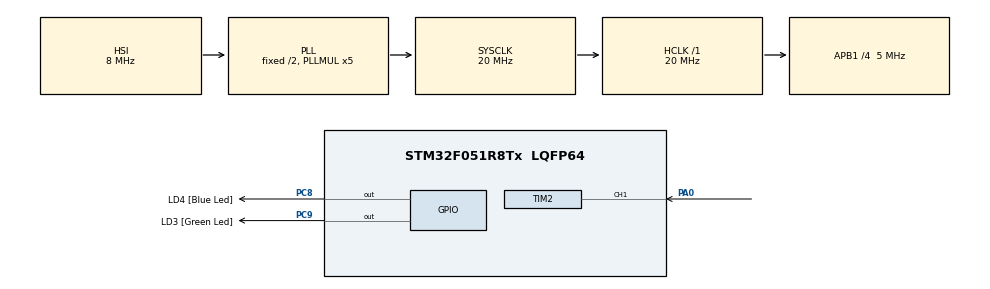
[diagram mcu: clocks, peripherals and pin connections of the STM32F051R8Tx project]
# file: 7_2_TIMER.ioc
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Mcu.Family=STM32F0
Mcu.Name=STM32F051R8Tx
Mcu.Package=LQFP64
NVIC.TIM2_IRQn=true\:0\:0\:false\:false\:true\:true\:true\:true
PA0.Signal=S_TIM2_CH1_ETR
PA13.GPIO_Label=SWDIO
PA13.Signal=SYS_SWDIO
PA14.GPIO_Label=SWCLK
PA14.Signal=SYS_SWCLK
PC8.GPIO_Label=LD4 [Blue Led]
PC8.Signal=GPIO_Output
PC9.GPIO_Label=LD3 [Green Led]
PC9.Signal=GPIO_Output
ProjectManager.HeapSize=0x200
ProjectManager.StackSize=0x400
ProjectManager.TargetToolchain=STM32CubeIDE
RCC.AHBFreq_Value=20000000
RCC.APB1CLKDivider=RCC_HCLK_DIV4
RCC.APB1Freq_Value=5000000
RCC.APB1TimFreq_Value=10000000
RCC.HCLKFreq_Value=20000000
RCC.PLLMUL=RCC_PLL_MUL5
RCC.SYSCLKFreq_VALUE=20000000
RCC.SYSCLKSource=RCC_SYSCLKSOURCE_PLLCLK
SH.S_TIM2_CH1_ETR.0=TIM2_CH1,Input_Capture1_from_TI1
TIM2.AutoReloadPreload=TIM_AUTORELOAD_PRELOAD_ENABLE
TIM2.Channel-Input_Capture1_from_TI1=TIM_CHANNEL_1
TIM2.Period=60000-1
TIM2.Prescaler=0
VP_TIM2_VS_ClockSourceINT.Mode=Internal
board=STM32F0DISCOVERY

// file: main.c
/* USER CODE BEGIN Header */
/**
  ******************************************************************************
  * @file           : main.c
  * @brief          : Main program body
  ******************************************************************************
  * @attention
  *
  * Copyright (c) 2023 STMicroelectronics.
  * All rights reserved.
  *
  * This software is licensed under terms that can be found in the LICENSE file
  * in the root directory of this software component.
  * If no LICENSE file comes with this software, it is provided AS-IS.
  *
  ******************************************************************************
  */
/* USER CODE END Header */
#include "main.h"

TIM_HandleTypeDef htim2;

void SystemClock_Config(void);
static void MX_GPIO_Init(void);
static void MX_TIM2_Init(void);

/* USER CODE BEGIN 0 */
float freq;
int ovc_value=0;
int start_flag=0;
int value_1=0;
int value_2=0;

/* USER CODE END 0 */

int main(void)
{

  /* MCU Configuration--------------------------------------------------------*/

  /* Reset of all peripherals, Initializes the Flash interface and the Systick. */
  HAL_Init();

  /* Configure the system clock */
  SystemClock_Config();

  /* Initialize all configured peripherals */
  MX_GPIO_Init();
  MX_TIM2_Init();
  /* USER CODE BEGIN 2 */
  HAL_TIM_Base_Start_IT(&htim2);
  HAL_TIM_IC_Start_IT(&htim2, TIM_CHANNEL_1);
  /* USER CODE END 2 */

  /* Infinite loop */
  while (1)
  {

  }
}

void SystemClock_Config(void)
{
  RCC_OscInitTypeDef RCC_OscInitStruct = {0};
  RCC_ClkInitTypeDef RCC_ClkInitStruct = {0};

  /** Initializes the RCC Oscillators according to the specified parameters
  * in the RCC_OscInitTypeDef structure.
  */
  RCC_OscInitStruct.OscillatorType = RCC_OSCILLATORTYPE_HSI;
  RCC_OscInitStruct.HSIState = RCC_HSI_ON;
  RCC_OscInitStruct.HSICalibrationValue = RCC_HSICALIBRATION_DEFAULT;
  RCC_OscInitStruct.PLL.PLLState = RCC_PLL_ON;
  RCC_OscInitStruct.PLL.PLLSource = RCC_PLLSOURCE_HSI;
  RCC_OscInitStruct.PLL.PLLMUL = RCC_PLL_MUL5;
  RCC_OscInitStruct.PLL.PREDIV = RCC_PREDIV_DIV1;
  if (HAL_RCC_OscConfig(&RCC_OscInitStruct) != HAL_OK)
  {
    Error_Handler();
  }

  /** Initializes the CPU, AHB and APB buses clocks
  */
  RCC_ClkInitStruct.ClockType = RCC_CLOCKTYPE_HCLK|RCC_CLOCKTYPE_SYSCLK
                              |RCC_CLOCKTYPE_PCLK1;
  RCC_ClkInitStruct.SYSCLKSource = RCC_SYSCLKSOURCE_PLLCLK;
  RCC_ClkInitStruct.AHBCLKDivider = RCC_SYSCLK_DIV1;
  RCC_ClkInitStruct.APB1CLKDivider = RCC_HCLK_DIV4;

  if (HAL_RCC_ClockConfig(&RCC_ClkInitStruct, FLASH_LATENCY_0) != HAL_OK)
  {
    Error_Handler();
  }
}

static void MX_TIM2_Init(void)
{

  TIM_ClockConfigTypeDef sClockSourceConfig = {0};
  TIM_MasterConfigTypeDef sMasterConfig = {0};
  TIM_IC_InitTypeDef sConfigIC = {0};

  htim2.Instance = TIM2;
  htim2.Init.Prescaler = 0;
  htim2.Init.CounterMode = TIM_COUNTERMODE_UP;
  htim2.Init.Period = 60000-1;
  htim2.Init.ClockDivision = TIM_CLOCKDIVISION_DIV1;
  htim2.Init.AutoReloadPreload = TIM_AUTORELOAD_PRELOAD_ENABLE;
  if (HAL_TIM_Base_Init(&htim2) != HAL_OK)
  {
    Error_Handler();
  }
  sClockSourceConfig.ClockSource = TIM_CLOCKSOURCE_INTERNAL;
  if (HAL_TIM_ConfigClockSource(&htim2, &sClockSourceConfig) != HAL_OK)
  {
    Error_Handler();
  }
  if (HAL_TIM_IC_Init(&htim2) != HAL_OK)
  {
    Error_Handler();
  }
  sMasterConfig.MasterOutputTrigger = TIM_TRGO_RESET;
  sMasterConfig.MasterSlaveMode = TIM_MASTERSLAVEMODE_DISABLE;
  if (HAL_TIMEx_MasterConfigSynchronization(&htim2, &sMasterConfig) != HAL_OK)
  {
    Error_Handler();
  }
  sConfigIC.ICPolarity = TIM_INPUTCHANNELPOLARITY_RISING;
  sConfigIC.ICSelection = TIM_ICSELECTION_DIRECTTI;
  sConfigIC.ICPrescaler = TIM_ICPSC_DIV1;
  sConfigIC.ICFilter = 0;
  if (HAL_TIM_IC_ConfigChannel(&htim2, &sConfigIC, TIM_CHANNEL_1) != HAL_OK)
  {
    Error_Handler();
  }

}

static void MX_GPIO_Init(void)
{
  GPIO_InitTypeDef GPIO_InitStruct = {0};

  /* GPIO Ports Clock Enable */
  __HAL_RCC_GPIOA_CLK_ENABLE();
  __HAL_RCC_GPIOC_CLK_ENABLE();

  /*Configure GPIO pin Output Level */
  HAL_GPIO_WritePin(GPIOC, LD4_Pin|LD3_Pin, GPIO_PIN_RESET);

  /*Configure GPIO pins : LD4_Pin LD3_Pin */
  GPIO_InitStruct.Pin = LD4_Pin|LD3_Pin;
  GPIO_InitStruct.Mode = GPIO_MODE_OUTPUT_PP;
  GPIO_InitStruct.Pull = GPIO_NOPULL;
  GPIO_InitStruct.Speed = GPIO_SPEED_FREQ_LOW;
  HAL_GPIO_Init(GPIOC, &GPIO_InitStruct);

}

/* USER CODE BEGIN 4 */
void HAL_TIM_PeriodElapsedCallback(TIM_HandleTypeDef *htim){
      UNUSED(htim);
      ovc_value++;
}
void HAL_TIM_IC_CaptureCallback(TIM_HandleTypeDef *htim){
	UNUSED(htim);
	if(!start_flag){
		value_1=HAL_TIM_ReadCapturedValue(&htim2,TIM_CHANNEL_1);
		ovc_value=0;
		start_flag=1;
	}
	else if(start_flag==1){
		value_2=HAL_TIM_ReadCapturedValue(&htim2,TIM_CHANNEL_1);
		freq=(float)10000/((value_2+(ovc_value*60000))-value_1);
		start_flag=0;
	}
}
/* USER CODE END 4 */

void Error_Handler(void)
{
  __disable_irq();
  while (1)
  {
  }
}
